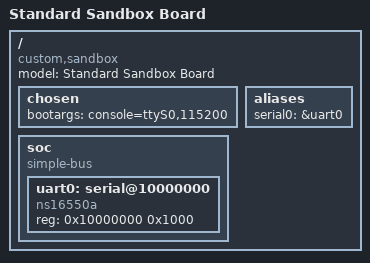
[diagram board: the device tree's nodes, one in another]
/dts-v1/;

#include "rk3399.dtsi"
#include "rk3399-opp.dtsi"

/ {
    #address-cells = <1>;
    #size-cells = <1>;
    model = "Standard Sandbox Board";
    compatible = "custom,sandbox";

    chosen {
        bootargs = "console=ttyS0,115200";
    };

    aliases {
        serial0 = &uart0;
    };

    soc {
        compatible = "simple-bus";
        ranges;

        uart0: serial@10000000 {
            compatible = "ns16550a";
            reg = <0x10000000 0x1000>;
            status = "disabled";
        };
    };
};

/* 允许在根节点外部通过引用标签来修改或追加属性 */
&uart0 {
    status = "okay";
};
